# MSP430FR2433 register map
Vendor: msp430gen; File version: v0.4.0-8-gde1e0b2
Registers are 16-bit, read-write, reset 0x0 unless marked. A register's access mark holds for its fields unless they carry their own. Offsets are from the block's base; lines under a group give offsets from that group; [hi:lo] are bit positions; {n}, {i} and the like mark numbered series; 'fields as' and 'values as' point back to an identical list; <NAME> marks a mode.

## Memory map
0x00000100 SFR — SFR Special Function Registers
0x00000120 PMM — PMM Power Management System
0x00000140 SYS — SYS System Module
0x00000180 CS — CS Clock System
0x000001A0 FRAM
0x000001C0 CRC16
0x000001CC WATCHDOG_TIMER
0x00000200 PORT_1_2
0x00000220 PORT_3
0x00000300 REAL_TIME_CLOCK
0x00000380 TIMER_0_A3
0x000003C0 TIMER_1_A3
0x00000400 TIMER_2_A2
0x00000440 TIMER_3_A2
0x000004C0 MPY_16 — MPY 16 Multiplier 16 Bit Mode
0x000004D0 MPY_32 — MPY 32 Multiplier 32 Bit Mode
0x00000500 USCI_A0_UART_MODE
0x00000500 USCI_A0_SPI_MODE
0x00000520 USCI_A1_UART_MODE
0x00000520 USCI_A1_SPI_MODE
0x00000540 USCI_B0_I2C_MODE
0x00000540 USCI_B0_SPI_MODE
0x00000660 BACKUP_MEMORY
0x00000700 ADC
0x0000FF80 _INTERRUPTS

## Interrupts
41 PORT2 (_INTERRUPTS) — 0xFFDA Port 2
42 PORT1 (_INTERRUPTS) — 0xFFDC Port 1
43 ADC (_INTERRUPTS) — 0xFFDE ADC
44 USCI_B0 (_INTERRUPTS) — 0xFFE0 USCI B0 Receive/Transmit
45 USCI_A1 (_INTERRUPTS) — 0xFFE2 USCI A1 Receive/Transmit
46 USCI_A0 (_INTERRUPTS) — 0xFFE4 USCI A0 Receive/Transmit
47 WDT (_INTERRUPTS) — 0xFFE6 Watchdog Timer
48 RTC (_INTERRUPTS) — 0xFFE8 RTC
49 TIMER3_A1 (_INTERRUPTS) — 0xFFEA Timer3_A2 CC1, TA
50 TIMER3_A0 (_INTERRUPTS) — 0xFFEC Timer3_A2 CC0
51 TIMER2_A1 (_INTERRUPTS) — 0xFFEE Timer2_A2 CC1, TA
52 TIMER2_A0 (_INTERRUPTS) — 0xFFF0 Timer2_A2 CC0
53 TIMER1_A1 (_INTERRUPTS) — 0xFFF2 Timer1_A3 CC1-2, TA
54 TIMER1_A0 (_INTERRUPTS) — 0xFFF4 Timer1_A3 CC0
55 TIMER0_A1 (_INTERRUPTS) — 0xFFF6 Timer0_A3 CC1-2, TA
56 TIMER0_A0 (_INTERRUPTS) — 0xFFE8 Timer0_A3 CC0
57 UNMI (_INTERRUPTS) — 0xFFFA User Non-maskable
58 SYSNMI (_INTERRUPTS) — 0xFFFC System Non-maskable

## PORT_1_2
Base 0x00000200
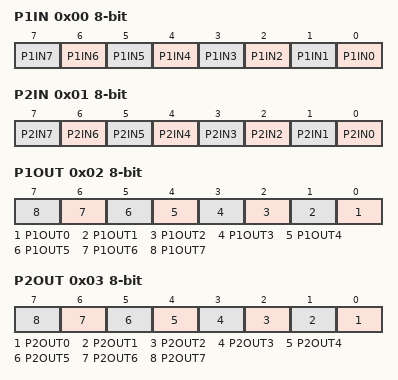
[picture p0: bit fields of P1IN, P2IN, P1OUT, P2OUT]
0x00 P1IN 8-bit — Port 1 Input
  [n] P1IN{n} (n=0..7)
0x01 P2IN 8-bit — Port 2 Input
  [n] P2IN{n} (n=0..7)
0x02 P1OUT 8-bit — Port 1 Output
  [n] P1OUT{n} (n=0..7)
0x03 P2OUT 8-bit — Port 2 Output
  [n] P2OUT{n} (n=0..7)
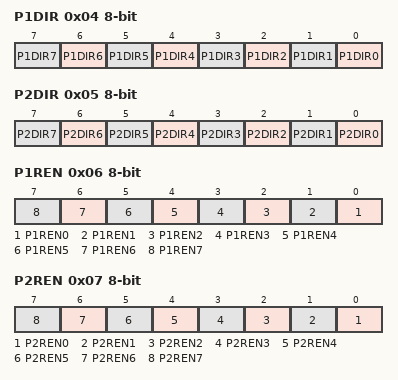
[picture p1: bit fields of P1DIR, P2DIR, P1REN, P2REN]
0x04 P1DIR 8-bit — Port 1 Direction
  [n] P1DIR{n} (n=0..7)
0x05 P2DIR 8-bit — Port 2 Direction
  [n] P2DIR{n} (n=0..7)
0x06 P1REN 8-bit — Port 1 Resistor Enable
  [n] P1REN{n} (n=0..7)
0x07 P2REN 8-bit — Port 2 Resistor Enable
  [n] P2REN{n} (n=0..7)
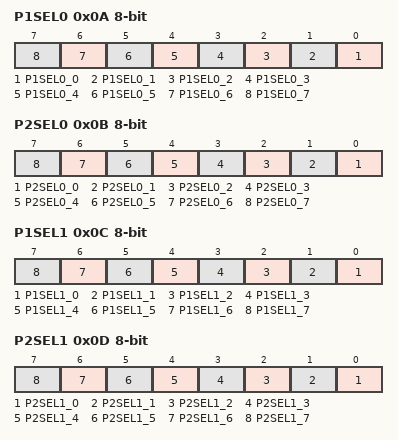
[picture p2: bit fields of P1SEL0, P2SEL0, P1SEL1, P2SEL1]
0x0A P1SEL0 8-bit — Port 1 Selection 0
  [n] P1SEL0_{n} (n=0..7)
0x0B P2SEL0 8-bit — Port 2 Selection 0
  [n] P2SEL0_{n} (n=0..7)
0x0C P1SEL1 8-bit — Port 1 Selection 1
  [n] P1SEL1_{n} (n=0..7)
0x0D P2SEL1 8-bit — Port 2 Selection 1
  [n] P2SEL1_{n} (n=0..7)
0x0E P1IV — Port 1 Interrupt Vector Word
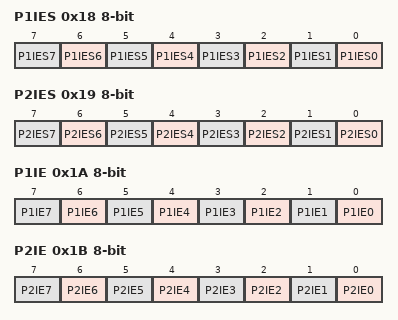
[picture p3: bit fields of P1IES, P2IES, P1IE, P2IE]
0x18 P1IES 8-bit — Port 1 Interrupt Edge Select
  [n] P1IES{n} (n=0..7)
0x19 P2IES 8-bit — Port 2 Interrupt Edge Select
  [n] P2IES{n} (n=0..7)
0x1A P1IE 8-bit — Port 1 Interrupt Enable
  [n] P1IE{n} (n=0..7)
0x1B P2IE 8-bit — Port 2 Interrupt Enable
  [n] P2IE{n} (n=0..7)
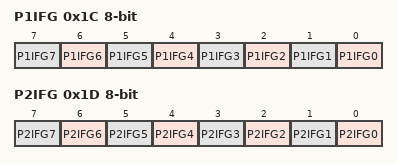
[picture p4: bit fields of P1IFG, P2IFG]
0x1C P1IFG 8-bit — Port 1 Interrupt Flag
  [n] P1IFG{n} (n=0..7)
0x1D P2IFG 8-bit — Port 2 Interrupt Flag
  [n] P2IFG{n} (n=0..7)
0x1E P2IV — Port 2 Interrupt Vector Word

## PORT_3
Base 0x00000220
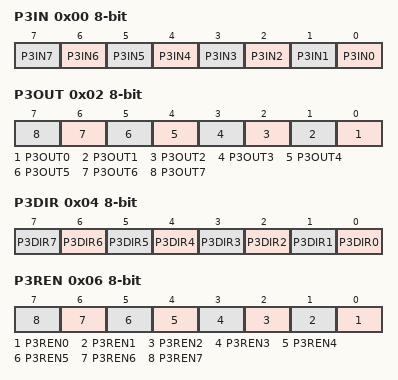
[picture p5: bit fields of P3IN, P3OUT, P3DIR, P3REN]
0x00 P3IN 8-bit — Port 3 Input
  [n] P3IN{n} (n=0..7)
0x02 P3OUT 8-bit — Port 3 Output
  [n] P3OUT{n} (n=0..7)
0x04 P3DIR 8-bit — Port 3 Direction
  [n] P3DIR{n} (n=0..7)
0x06 P3REN 8-bit — Port 3 Resistor Enable
  [n] P3REN{n} (n=0..7)
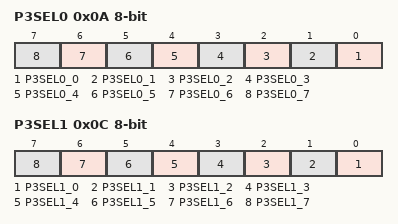
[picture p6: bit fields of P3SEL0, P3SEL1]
0x0A P3SEL0 8-bit — Port 3 Selection0
  [n] P3SEL0_{n} (n=0..7)
0x0C P3SEL1 8-bit — Port 3 Selection1
  [n] P3SEL1_{n} (n=0..7)

## USCI_A0_UART_MODE
Base 0x00000500
0x00 UCA0CTL1 8-bit — USCI A0 Control Register 1
0x01 UCA0CTL0 8-bit — USCI A0 Control Register 0
0x02 UCA0CTLW1 — USCI A0 Control Word Register 1
  [1:0] UCGLIT — USCI Deglitch Time Bit 1
    {v}=USCI Deglitch time: {v} (v=0..3)
0x06 UCA0BR0 8-bit — USCI A0 Baud Rate 0
0x07 UCA0BR1 8-bit — USCI A0 Baud Rate 1
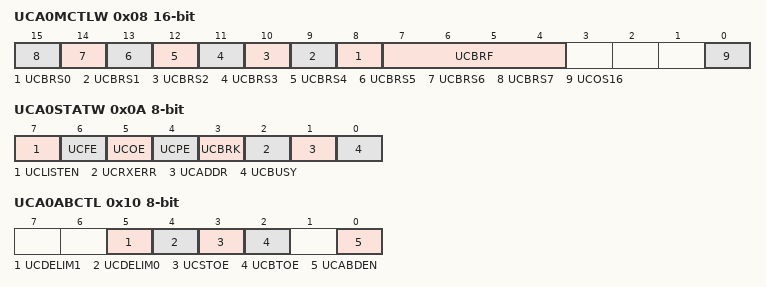
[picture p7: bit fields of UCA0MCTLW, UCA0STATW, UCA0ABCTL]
0x08 UCA0MCTLW — USCI A0 Modulation Control
  [n+8] UCBRS{n} (n=0..7) — USCI Second Stage Modulation Select {n}
  [7:4] UCBRF — USCI First Stage Modulation Select 3
    {v}=USCI First Stage Modulation: {v} (v=0..9); 10=USCI First Stage Modulation: A; 11=USCI First Stage Modulation: B; 12=USCI First Stage Modulation: C; 13=USCI First Stage Modulation: D; 14=USCI First Stage Modulation: E; 15=USCI First Stage Modulation: F
  [0] UCOS16 — USCI 16-times Oversampling enable
0x0A UCA0STATW 8-bit — USCI A0 Status Register
  [7] UCLISTEN — USCI Listen mode
  [6] UCFE — USCI Frame Error Flag
  [5] UCOE — USCI Overrun Error Flag
  [4] UCPE — USCI Parity Error Flag
  [3] UCBRK — USCI Break received
  [2] UCRXERR — USCI RX Error Flag
  [1] UCADDR — USCI Address received Flag
  [0] UCBUSY — USCI Busy Flag
0x0C UCA0RXBUF — USCI A0 Receive Buffer
0x0E UCA0TXBUF — USCI A0 Transmit Buffer
0x10 UCA0ABCTL 8-bit — USCI A0 LIN Control
  [5] UCDELIM1 — Break Sync Delimiter 1
  [4] UCDELIM0 — Break Sync Delimiter 0
  [3] UCSTOE — Sync-Field Timeout error
  [2] UCBTOE — Break Timeout error
  [0] UCABDEN — Auto Baud Rate detect enable
0x12 UCA0IRTCTL 8-bit — USCI A0 IrDA Transmit Control
0x13 UCA0IRRCTL 8-bit — USCI A0 IrDA Receive Control
0x1E UCA0IV — USCI A0 Interrupt Vector Register
